# STM32L4x1_v1r1 register map
File version: 1.0
Registers are 32-bit, read-write, reset 0x0 unless marked. A register's access mark holds for its fields unless they carry their own. Offsets are from the block's base; [hi:lo] are bit positions; {n}, {i} and the like mark numbered series.

## NVIC — Nested Vectored Interrupt Controller
Base 0xE000E000
0x04 ICTR ro — Interrupt Controller Type Register
  [3:0] INTLINESNUM — Total number of interrupt lines in groups
{0x100+4i} ISER{i} (i=0..2) — Interrupt Set-Enable Register
  [31:0] SETENA
{0x180+4i} ICER{i} (i=0..2) — Interrupt Clear-Enable Register
  [31:0] CLRENA
{0x200+4i} ISPR{i} (i=0..2) — Interrupt Set-Pending Register
  [31:0] SETPEND
{0x280+4i} ICPR{i} (i=0..2) — Interrupt Clear-Pending Register
  [31:0] CLRPEND
{0x300+4i} IABR{i} ro (i=0..2) — Interrupt Active Bit Register
  [31:0] ACTIVE
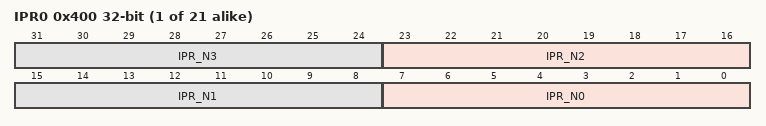
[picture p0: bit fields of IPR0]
{0x400+4i} IPR{i} (i=0..20) — Interrupt Priority Register
  [8n+7:8n] IPR_N{n} (n=0..3)
0xF00 STIR wo — Software Triggered Interrupt Register
  [8:0] INTID — interrupt to be triggered

## CRS — Clock recovery system
Base 0x40006000
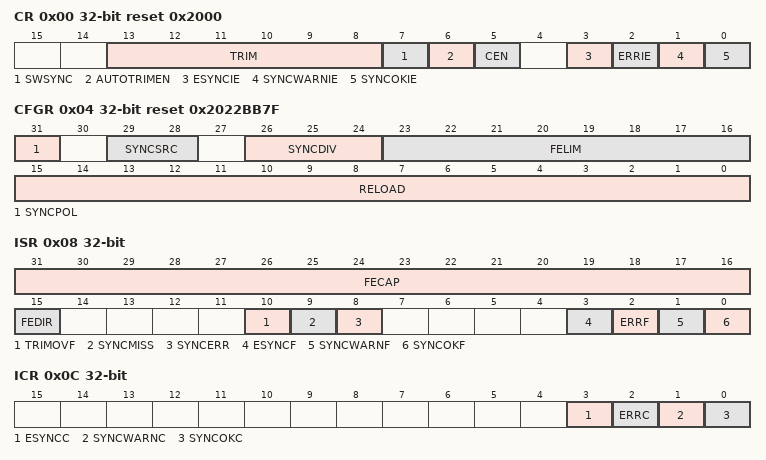
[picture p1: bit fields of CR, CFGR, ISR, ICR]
0x00 CR reset 0x2000 — control register
  [13:8] TRIM — HSI48 oscillator smooth trimming
  [7] SWSYNC — Generate software SYNC event
  [6] AUTOTRIMEN — Automatic trimming enable
  [5] CEN — Frequency error counter enable
  [3] ESYNCIE — Expected SYNC interrupt enable
  [2] ERRIE — Synchronization or trimming error interrupt enable
  [1] SYNCWARNIE — SYNC warning interrupt enable
  [0] SYNCOKIE — SYNC event OK interrupt enable
0x04 CFGR reset 0x2022BB7F — configuration register
  [31] SYNCPOL — SYNC polarity selection
  [29:28] SYNCSRC — SYNC signal source selection
  [26:24] SYNCDIV — SYNC divider
  [23:16] FELIM — Frequency error limit
  [15:0] RELOAD — Counter reload value
0x08 ISR ro — interrupt and status register
  [31:16] FECAP — Frequency error capture
  [15] FEDIR — Frequency error direction
  [10] TRIMOVF — Trimming overflow or underflow
  [9] SYNCMISS — SYNC missed
  [8] SYNCERR — SYNC error
  [3] ESYNCF — Expected SYNC flag
  [2] ERRF — Error flag
  [1] SYNCWARNF — SYNC warning flag
  [0] SYNCOKF — SYNC event OK flag
0x0C ICR — interrupt flag clear register
  [3] ESYNCC — Expected SYNC clear flag
  [2] ERRC — Error clear flag
  [1] SYNCWARNC — SYNC warning clear flag
  [0] SYNCOKC — SYNC event OK clear flag

## USB_SRAM — Universal serial bus full-speed device interface
Base 0x40006C00
Same registers: USB_FS 0x40006800
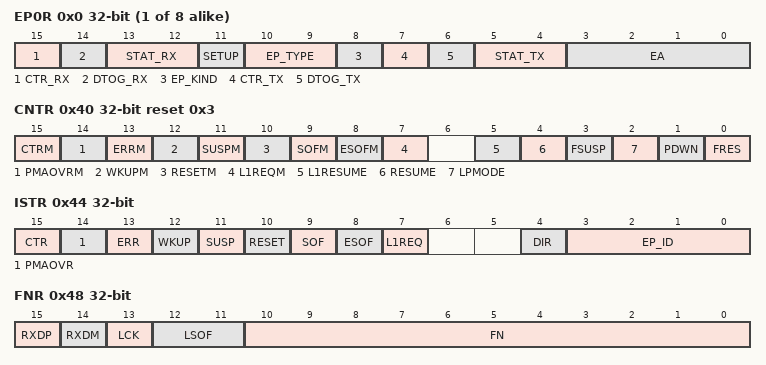
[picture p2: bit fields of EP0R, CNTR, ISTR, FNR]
{0x0+4i} EP{i}R (i=0..7) — endpoint {i} register
  [15] CTR_RX — Correct transfer for reception
  [14] DTOG_RX — Data Toggle, for reception transfers
  [13:12] STAT_RX — Status bits, for reception transfers
  [11] SETUP — Setup transaction completed
  [10:9] EP_TYPE — Endpoint type
  [8] EP_KIND — Endpoint kind
  [7] CTR_TX — Correct Transfer for transmission
  [6] DTOG_TX — Data Toggle, for transmission transfers
  [5:4] STAT_TX — Status bits, for transmission transfers
  [3:0] EA — Endpoint address
0x40 CNTR reset 0x3 — control register
  [15] CTRM — Correct transfer interrupt mask
  [14] PMAOVRM — Packet memory area over / underrun interrupt mask
  [13] ERRM — Error interrupt mask
  [12] WKUPM — Wakeup interrupt mask
  [11] SUSPM — Suspend mode interrupt mask
  [10] RESETM — USB reset interrupt mask
  [9] SOFM — Start of frame interrupt mask
  [8] ESOFM — Expected start of frame interrupt mask
  [7] L1REQM — LPM L1 state request interrupt mask
  [5] L1RESUME — LPM L1 Resume request
  [4] RESUME — Resume request
  [3] FSUSP — Force suspend
  [2] LPMODE — Low-power mode
  [1] PDWN — Power down
  [0] FRES — Force USB Reset
0x44 ISTR access per field — interrupt status register
  [15] CTR ro — Correct transfer
  [14] PMAOVR rw — Packet memory area over / underrun
  [13] ERR rw — Error
  [12] WKUP rw — Wakeup
  [11] SUSP rw — Suspend mode request
  [10] RESET rw — reset request
  [9] SOF rw — start of frame
  [8] ESOF rw — Expected start frame
  [7] L1REQ rw — LPM L1 state request
  [4] DIR ro — Direction of transaction
  [3:0] EP_ID ro — Endpoint Identifier
0x48 FNR ro — frame number register
  [15] RXDP — Receive data + line status
  [14] RXDM — Receive data - line status
  [13] LCK — Locked
  [12:11] LSOF — Lost SOF
  [10:0] FN — Frame number
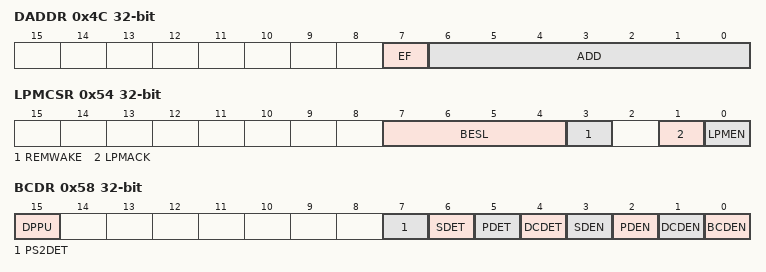
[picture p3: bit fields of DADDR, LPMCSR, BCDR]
0x4C DADDR — device address
  [7] EF — Enable function
  [6:0] ADD — Device address
0x50 BTABLE — Buffer table address
  [15:3] BTABLE — Buffer table
0x54 LPMCSR access per field — LPM control and status register
  [7:4] BESL ro — BESL value
  [3] REMWAKE ro — bRemoteWake value
  [1] LPMACK rw — LPM Token acknowledge enable
  [0] LPMEN rw — LPM support enable
0x58 BCDR access per field — Battery charging detector
  [15] DPPU rw — DP pull-up control
  [7] PS2DET ro — DM pull-up detection status
  [6] SDET ro — Secondary detection
  [5] PDET ro — Primary detection
  [4] DCDET ro — Data contact detection
  [3] SDEN rw — Secondary detection
  [2] PDEN rw — Primary detection
  [1] DCDEN rw — Data contact detection
  [0] BCDEN rw — Battery charging detector

## QUADSPI — QuadSPI interface
Base 0xA0001000
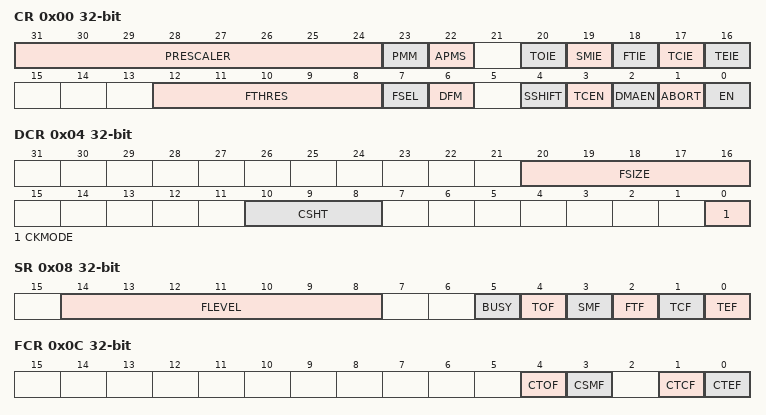
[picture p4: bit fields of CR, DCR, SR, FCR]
0x00 CR — control register
  [31:24] PRESCALER — Clock prescaler
  [23] PMM — Polling match mode
  [22] APMS — Automatic poll mode stop
  [20] TOIE — TimeOut interrupt enable
  [19] SMIE — Status match interrupt enable
  [18] FTIE — FIFO threshold interrupt enable
  [17] TCIE — Transfer complete interrupt enable
  [16] TEIE — Transfer error interrupt enable
  [12:8] FTHRES — IFO threshold level
  [7] FSEL — FLASH memory selection
  [6] DFM — Dual-flash mode
  [4] SSHIFT — Sample shift
  [3] TCEN — Timeout counter enable
  [2] DMAEN — DMA enable
  [1] ABORT — Abort request
  [0] EN — Enable
0x04 DCR — device configuration register
  [20:16] FSIZE — FLASH memory size
  [10:8] CSHT — Chip select high time
  [0] CKMODE — Mode 0 / mode 3
0x08 SR ro — status register
  [14:8] FLEVEL — FIFO level
  [5] BUSY
  [4] TOF — Timeout flag
  [3] SMF — Status match flag
  [2] FTF — FIFO threshold flag
  [1] TCF — Transfer complete flag
  [0] TEF — Transfer error flag
0x0C FCR — flag clear register
  [4] CTOF — Clear timeout flag
  [3] CSMF — Clear status match flag
  [1] CTCF — Clear transfer complete flag
  [0] CTEF — Clear transfer error flag
0x10 DLR — data length register
  [31:0] DL — Data length
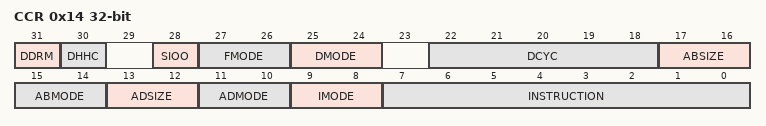
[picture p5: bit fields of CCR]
0x14 CCR — communication configuration register
  [31] DDRM — Double data rate mode
  [30] DHHC — DDR hold half cycle
  [28] SIOO — Send instruction only once mode
  [27:26] FMODE — Functional mode
  [25:24] DMODE — Data mode
  [22:18] DCYC — Number of dummy cycles
  [17:16] ABSIZE — Alternate bytes size
  [15:14] ABMODE — Alternate bytes mode
  [13:12] ADSIZE — Address size
  [11:10] ADMODE — Address mode
  [9:8] IMODE — Instruction mode
  [7:0] INSTRUCTION
0x18 AR — address register
  [31:0] ADDRESS
0x1C ABR
  [31:0] ALTERNATE
0x20 DR — data register
  [31:0] DATA
0x24 PSMKR — polling status mask register
  [31:0] MASK — Status mask
0x28 PSMAR — polling status match register
  [31:0] MATCH — Status match
0x2C PIR — polling interval register
  [15:0] INTERVAL — Polling interval
0x30 LPTR — low-power timeout register
  [15:0] TIMEOUT — Timeout period
